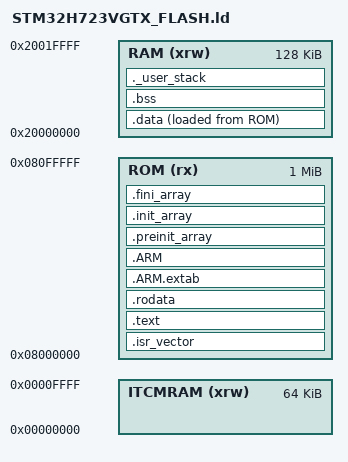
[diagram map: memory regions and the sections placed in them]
/* Adapted from STM32CubeH7 V1.13.0 STM32H723ZGTX_FLASH.ld. */
ENTRY(Reset_Handler)

_estack = ORIGIN(RAM) + LENGTH(RAM);
_Min_Heap_Size = 0;
_Min_Stack_Size = 0x800;

MEMORY
{
  ITCMRAM (xrw) : ORIGIN = 0x00000000, LENGTH = 64K
  RAM     (xrw) : ORIGIN = 0x20000000, LENGTH = 128K
  ROM     (rx)  : ORIGIN = 0x08000000, LENGTH = 1024K
}

SECTIONS
{
  .isr_vector :
  {
    . = ALIGN(4);
    KEEP(*(.isr_vector))
    . = ALIGN(4);
  } >ROM

  .text :
  {
    . = ALIGN(4);
    *(.text) *(.text*) *(.glue_7) *(.glue_7t) *(.eh_frame)
    KEEP(*(.init)) KEEP(*(.fini))
    . = ALIGN(4);
    _etext = .;
  } >ROM

  .rodata :
  {
    . = ALIGN(4);
    *(.rodata) *(.rodata*)
    . = ALIGN(4);
  } >ROM

  .ARM.extab (READONLY) :
  {
    *(.ARM.extab* .gnu.linkonce.armextab.*)
  } >ROM

  .ARM (READONLY) :
  {
    __exidx_start = .;
    *(.ARM.exidx*)
    __exidx_end = .;
  } >ROM

  .preinit_array (READONLY) :
  {
    PROVIDE_HIDDEN(__preinit_array_start = .);
    KEEP(*(.preinit_array*))
    PROVIDE_HIDDEN(__preinit_array_end = .);
  } >ROM

  .init_array (READONLY) :
  {
    PROVIDE_HIDDEN(__init_array_start = .);
    KEEP(*(SORT(.init_array.*))) KEEP(*(.init_array*))
    PROVIDE_HIDDEN(__init_array_end = .);
  } >ROM

  .fini_array (READONLY) :
  {
    PROVIDE_HIDDEN(__fini_array_start = .);
    KEEP(*(SORT(.fini_array.*))) KEEP(*(.fini_array*))
    PROVIDE_HIDDEN(__fini_array_end = .);
  } >ROM

  _sidata = LOADADDR(.data);
  .data :
  {
    . = ALIGN(4);
    _sdata = .;
    *(.data) *(.data*)
    . = ALIGN(4);
    _edata = .;
  } >RAM AT>ROM

  .bss :
  {
    . = ALIGN(4);
    _sbss = .;
    __bss_start__ = _sbss;
    *(.bss) *(.bss*) *(COMMON)
    . = ALIGN(4);
    _ebss = .;
    __bss_end__ = _ebss;
  } >RAM

  ._user_stack :
  {
    . = ALIGN(8);
    PROVIDE(end = .);
    PROVIDE(_end = .);
    . = . + _Min_Stack_Size;
    . = ALIGN(8);
  } >RAM

  ASSERT(_Min_Heap_Size == 0, "Dynamic heap must remain disabled")
  .ARM.attributes 0 : { *(.ARM.attributes) }
}
